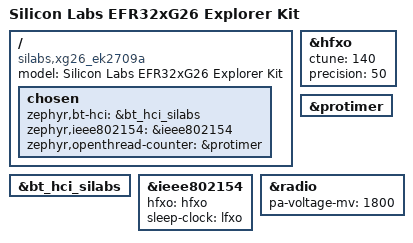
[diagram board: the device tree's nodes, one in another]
/*
 * Copyright The Zephyr Project Contributors
 *
 * SPDX-License-Identifier: Apache-2.0
 */

/dts-v1/;
#include <silabs/xg26/efr32mg26b510f3200im48.dtsi>
#include "xg26_explorer_kit.dtsi"

/ {
	compatible = "silabs,xg26_ek2709a", "silabs,efr32mg26";
	model = "Silicon Labs EFR32xG26 Explorer Kit";

	chosen {
		zephyr,bt-hci = &bt_hci_silabs;
		zephyr,ieee802154 = &ieee802154;
		zephyr,openthread-counter = &protimer;
	};
};

&bt_hci_silabs {
	status = "okay";
};

&ieee802154 {
	hfxo = <&hfxo>;
	sleep-clock = <&lfxo>;
	status = "okay";
};

&hfxo {
	ctune = <140>;
	precision = <50>;
	status = "okay";
};

&protimer {
	status = "okay";
};

&radio {
	pa-voltage-mv = <1800>;
};
